# XHSC_HC32F175 register map
Vendor: XHSC Co.Ltd; Series: ARMCM0P; File version: 1.0
CPU: CM0P r0p0, little endian, no MPU, no FPU, 3 interrupt priority bits
Registers are 32-bit, read-write, reset 0x0 unless marked. A register's access mark holds for its fields unless they carry their own. Offsets are from the block's base; [hi:lo] are bit positions; {n}, {i} and the like mark numbered series.

## GPIO
Base 0x40020000
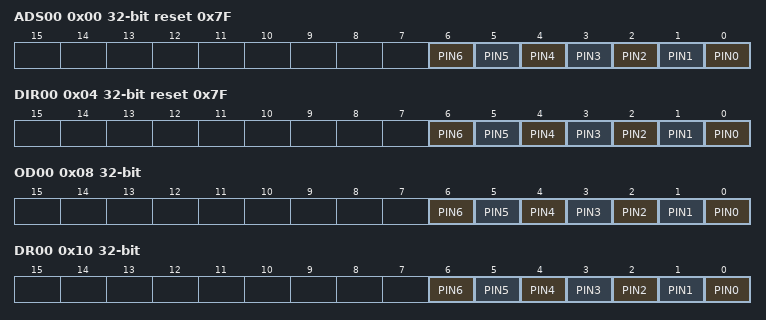
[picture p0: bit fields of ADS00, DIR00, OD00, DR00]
0x00 ADS00 reset 0x7F
  [n] PIN{n} (n=0..6)
0x04 DIR00 reset 0x7F
  [n] PIN{n} (n=0..6)
0x08 OD00
  [n] PIN{n} (n=0..6)
0x10 DR00
  [n] PIN{n} (n=0..6)
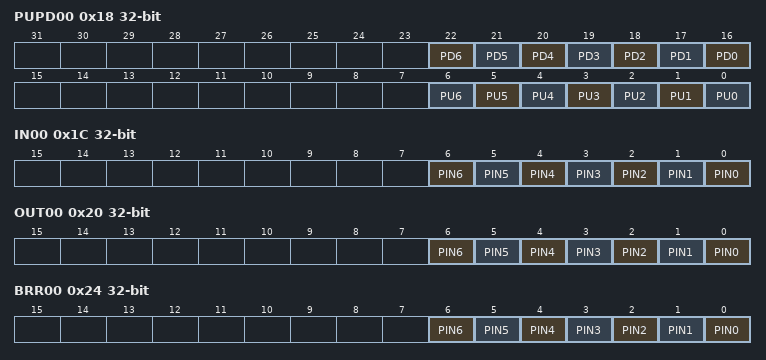
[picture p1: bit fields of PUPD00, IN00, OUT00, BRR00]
0x18 PUPD00
  [n+16] PD{n} (n=0..6), [n] PU{n} (n=0..6)
0x1C IN00 ro
  [n] PIN{n} (n=0..6)
0x20 OUT00
  [n] PIN{n} (n=0..6)
0x24 BRR00 wo
  [n] PIN{n} (n=0..6)
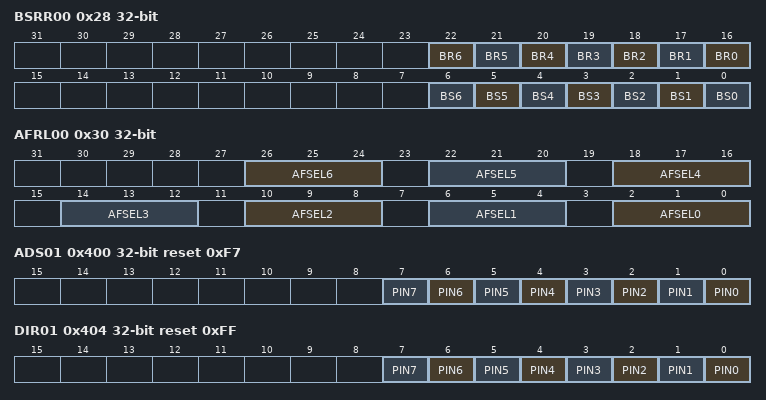
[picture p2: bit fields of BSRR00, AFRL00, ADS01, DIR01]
0x28 BSRR00 wo
  [n+16] BR{n} (n=0..6), [n] BS{n} (n=0..6)
0x30 AFRL00
  [4n+2:4n] AFSEL{n} (n=0..6)
{0x80+0x400*i} LOCK{i:02} wo (i=0..8)
  [31:0] LOCK
0x400 ADS01 reset 0xF7
  [n] PIN{n} (n=0..7)
0x404 DIR01 reset 0xFF
  [n] PIN{n} (n=0..7)
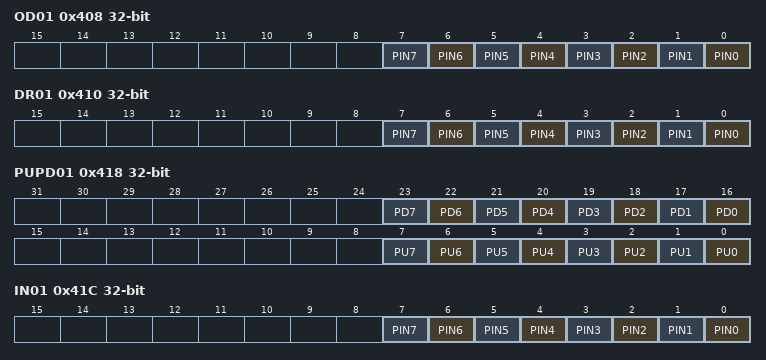
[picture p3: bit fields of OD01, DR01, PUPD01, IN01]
0x408 OD01
  [n] PIN{n} (n=0..7)
0x410 DR01
  [n] PIN{n} (n=0..7)
0x418 PUPD01
  [n+16] PD{n} (n=0..7), [n] PU{n} (n=0..7)
0x41C IN01 ro
  [n] PIN{n} (n=0..7)
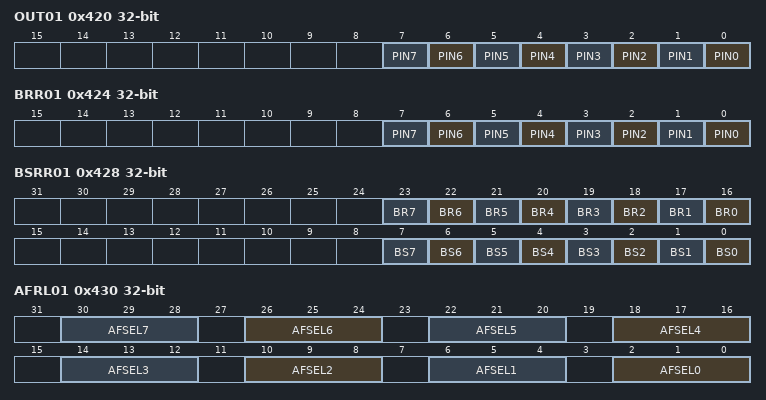
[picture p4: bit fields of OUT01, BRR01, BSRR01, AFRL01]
0x420 OUT01
  [n] PIN{n} (n=0..7)
0x424 BRR01 wo
  [n] PIN{n} (n=0..7)
0x428 BSRR01 wo
  [n+16] BR{n} (n=0..7), [n] BS{n} (n=0..7)
0x430 AFRL01
  [4n+2:4n] AFSEL{n} (n=0..7)
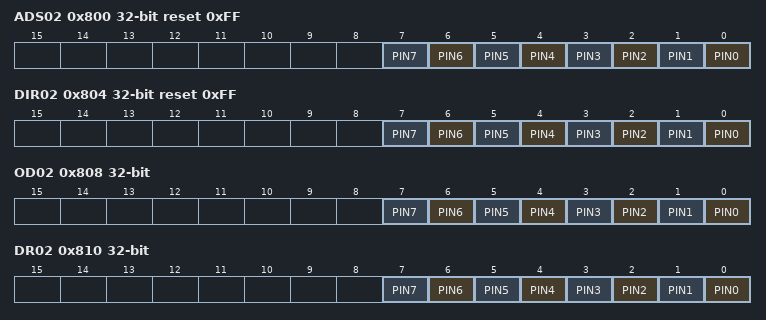
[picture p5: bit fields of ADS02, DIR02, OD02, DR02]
0x800 ADS02 reset 0xFF
  [n] PIN{n} (n=0..7)
0x804 DIR02 reset 0xFF
  [n] PIN{n} (n=0..7)
0x808 OD02
  [n] PIN{n} (n=0..7)
0x810 DR02
  [n] PIN{n} (n=0..7)
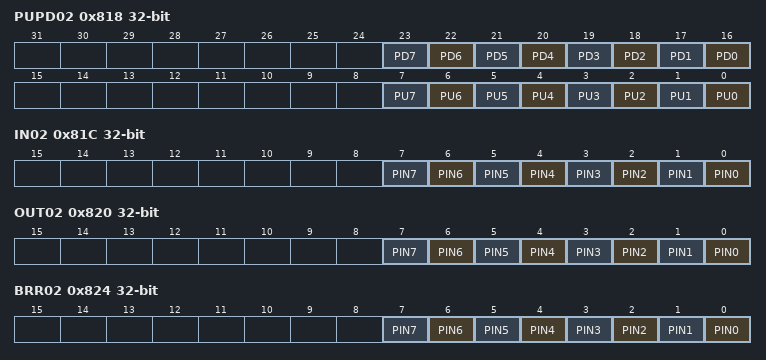
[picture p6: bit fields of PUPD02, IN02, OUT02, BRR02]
0x818 PUPD02
  [n+16] PD{n} (n=0..7), [n] PU{n} (n=0..7)
0x81C IN02 ro
  [n] PIN{n} (n=0..7)
0x820 OUT02
  [n] PIN{n} (n=0..7)
0x824 BRR02 wo
  [n] PIN{n} (n=0..7)
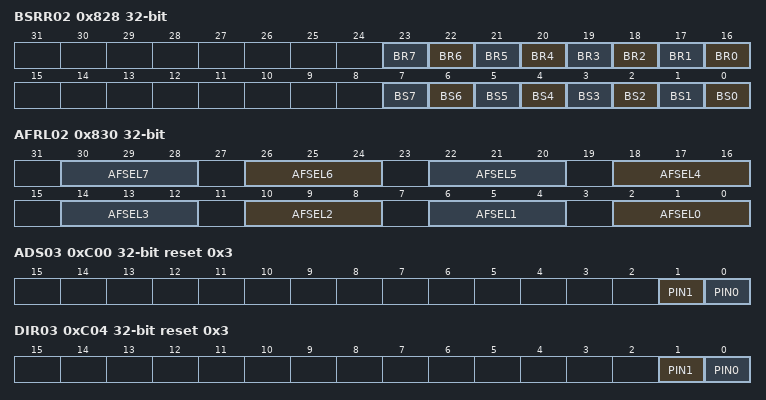
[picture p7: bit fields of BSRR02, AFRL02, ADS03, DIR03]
0x828 BSRR02 wo
  [n+16] BR{n} (n=0..7), [n] BS{n} (n=0..7)
0x830 AFRL02
  [4n+2:4n] AFSEL{n} (n=0..7)
0xC00 ADS03 reset 0x3
  [1] PIN1, [0] PIN0
0xC04 DIR03 reset 0x3
  [1] PIN1, [0] PIN0
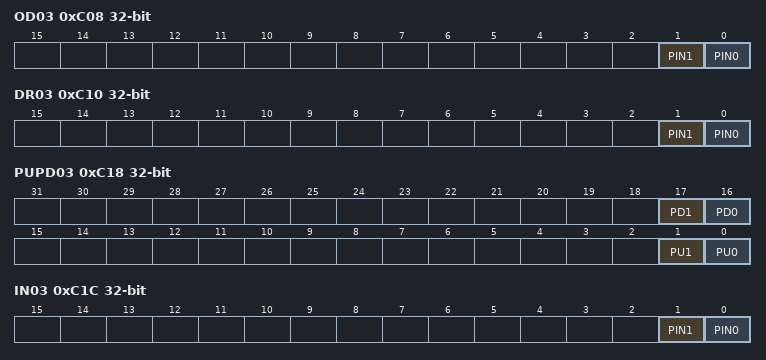
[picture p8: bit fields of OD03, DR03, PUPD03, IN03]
0xC08 OD03
  [1] PIN1, [0] PIN0
0xC10 DR03
  [1] PIN1, [0] PIN0
0xC18 PUPD03
  [17] PD1, [16] PD0, [1] PU1, [0] PU0
0xC1C IN03 ro
  [1] PIN1, [0] PIN0
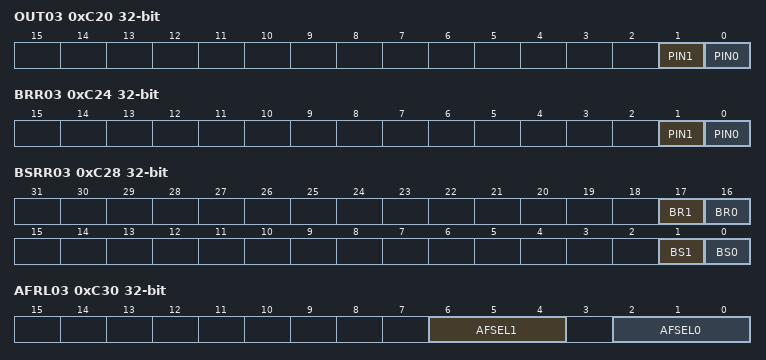
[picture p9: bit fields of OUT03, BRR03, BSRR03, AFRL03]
0xC20 OUT03
  [1] PIN1, [0] PIN0
0xC24 BRR03 wo
  [1] PIN1, [0] PIN0
0xC28 BSRR03 wo
  [17] BR1, [16] BR0, [1] BS1, [0] BS0
0xC30 AFRL03
  [6:4] AFSEL1, [2:0] AFSEL0
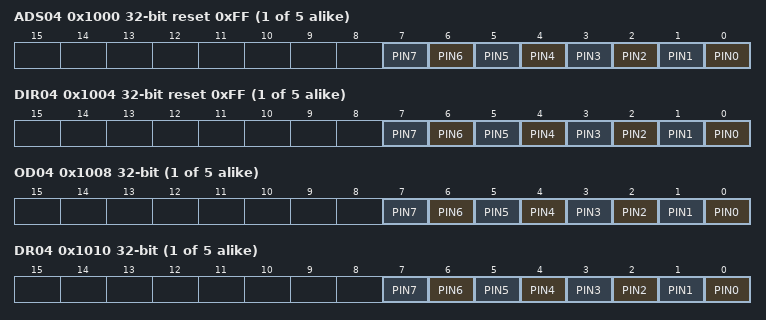
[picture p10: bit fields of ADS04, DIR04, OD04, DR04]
{0x0+0x400*i} ADS{i:02} reset 0xFF (i=4..8)
  [n] PIN{n} (n=0..7)
{0x4+0x400*i} DIR{i:02} reset 0xFF (i=4..8)
  [n] PIN{n} (n=0..7)
{0x8+0x400*i} OD{i:02} (i=4..8)
  [n] PIN{n} (n=0..7)
{0x10+0x400*i} DR{i:02} (i=4..8)
  [n] PIN{n} (n=0..7)
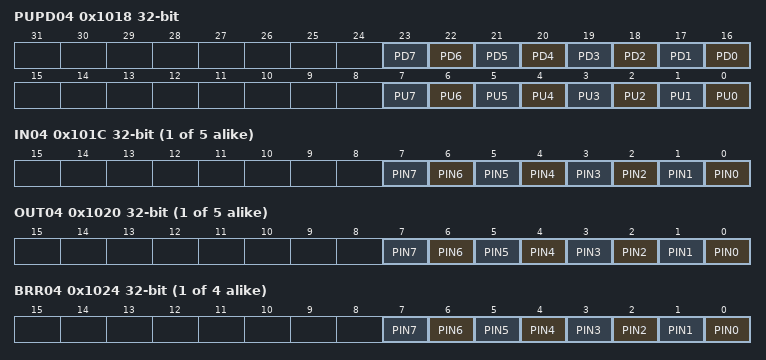
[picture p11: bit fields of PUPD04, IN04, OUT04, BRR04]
0x1018 PUPD04
  [n+16] PD{n} (n=0..7), [n] PU{n} (n=0..7)
{0x1C+0x400*i} IN{i:02} ro (i=4..8)
  [n] PIN{n} (n=0..7)
{0x20+0x400*i} OUT{i:02} (i=4..8)
  [n] PIN{n} (n=0..7)
{0x24+0x400*i} BRR{i:02} wo (i=4..7)
  [n] PIN{n} (n=0..7)
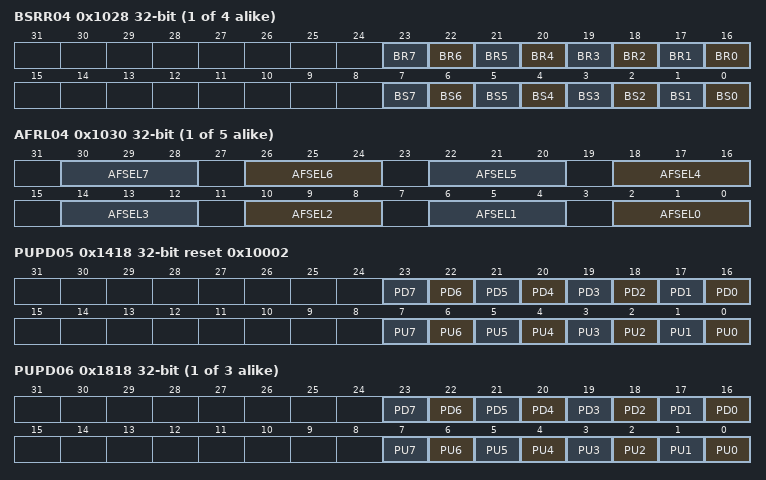
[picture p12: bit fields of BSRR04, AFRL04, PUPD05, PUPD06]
{0x28+0x400*i} BSRR{i:02} wo (i=4..7)
  [n+16] BR{n} (n=0..7), [n] BS{n} (n=0..7)
{0x30+0x400*i} AFRL{i:02} (i=4..8)
  [4n+2:4n] AFSEL{n} (n=0..7)
0x1418 PUPD05 reset 0x10002
  [n+16] PD{n} (n=0..7), [n] PU{n} (n=0..7)
{0x18+0x400*i} PUPD{i:02} (i=6..8)
  [n+16] PD{n} (n=0..7), [n] PU{n} (n=0..7)
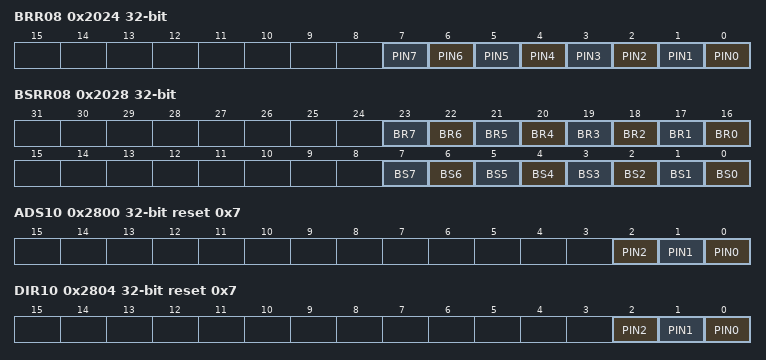
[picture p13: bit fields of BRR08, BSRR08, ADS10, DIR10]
0x2024 BRR08
  [n] PIN{n} wo (n=0..7)
0x2028 BSRR08
  [n+16] BR{n} wo (n=0..7), [n] BS{n} wo (n=0..7)
0x2800 ADS10 reset 0x7
  [2] PIN2, [1] PIN1, [0] PIN0
0x2804 DIR10 reset 0x7
  [2] PIN2, [1] PIN1, [0] PIN0
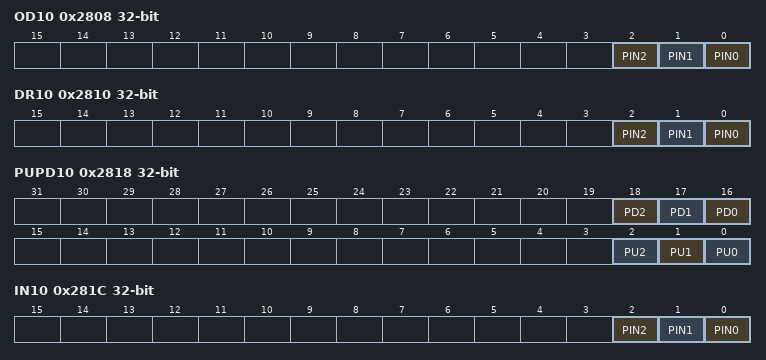
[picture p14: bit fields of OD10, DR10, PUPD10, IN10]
0x2808 OD10
  [2] PIN2, [1] PIN1, [0] PIN0
0x2810 DR10
  [2] PIN2, [1] PIN1, [0] PIN0
0x2818 PUPD10
  [18] PD2, [17] PD1, [16] PD0, [2] PU2, [1] PU1, [0] PU0
0x281C IN10 ro
  [2] PIN2, [1] PIN1, [0] PIN0
0x2820 OUT10
  [2] PIN2, [1] PIN1, [0] PIN0
0x2824 BRR10 wo
  [2] PIN2, [1] PIN1, [0] PIN0
0x2828 BSRR10 wo
  [18] BR2, [17] BR1, [16] BR0, [2] BS2, [1] BS1, [0] BS0
0x2830 AFRL10
  [10:8] AFSEL2, [6:4] AFSEL1, [2:0] AFSEL0
{0x80+0x400*i} LOCK{i} wo (i=10..15)
  [31:0] LOCK
0x2C00 ADS11 reset 0x3
  [1] PIN1, [0] PIN0
0x2C04 DIR11 reset 0x3
  [1] PIN1, [0] PIN0
0x2C08 OD11
  [1] PIN1, [0] PIN0
0x2C10 DR11
  [1] PIN1, [0] PIN0
0x2C18 PUPD11
  [17] PD1, [16] PD0, [1] PU1, [0] PU0
0x2C1C IN11 ro
  [1] PIN1, [0] PIN0
0x2C20 OUT11
  [1] PIN1, [0] PIN0
0x2C24 BRR11 wo
  [1] PIN1, [0] PIN0
0x2C28 BSRR11 wo
  [17] BR1, [16] BR0, [1] BS1, [0] BS0
0x2C30 AFRL11
  [6:4] AFSEL1, [2:0] AFSEL0
0x3000 ADS12 reset 0x1F
  [n] PIN{n} (n=0..4)
0x3004 DIR12 reset 0x1F
  [n] PIN{n} (n=0..4)
0x3008 OD12
  [n] PIN{n} (n=0..4)
0x3010 DR12
  [n] PIN{n} (n=0..4)
0x3018 PUPD12
  [n+16] PD{n} (n=0..4), [n] PU{n} (n=0..4)
0x301C IN12 ro
  [n] PIN{n} (n=0..4)
0x3020 OUT12
  [n] PIN{n} (n=0..4)
0x3024 BRR12 wo
  [n] PIN{n} (n=0..4)
0x3028 BSRR12 wo
  [n+16] BR{n} (n=0..4), [n] BS{n} (n=0..4)
0x3030 AFRL12
  [4n+2:4n] AFSEL{n} (n=0..4)
0x3400 ADS13 reset 0x81
  [7] PIN7, [0] PIN0
0x3404 DIR13 reset 0x81
  [7] PIN7, [0] PIN0
0x3408 OD13
  [7] PIN7, [0] PIN0
0x3410 DR13
  [7] PIN7, [0] PIN0
0x3418 PUPD13
  [23] PD7, [16] PD0, [7] PU7, [0] PU0
0x341C IN13 ro
  [7] PIN7, [0] PIN0
0x3420 OUT13
  [7] PIN7, [0] PIN0
0x3424 BRR13 wo
  [7] PIN7, [0] PIN0
0x3428 BSRR13 wo
  [23] BR7, [16] BR0, [7] BS7, [0] BS0
0x3430 AFRL13
  [30:28] AFSEL7, [2:0] AFSEL0
0x3800 ADS14 reset 0xFF
  [n] PIN{n} (n=0..7)
0x3804 DIR14 reset 0xFF
  [n] PIN{n} (n=0..7)
0x3808 OD14
  [n] PIN{n} (n=0..7)
0x3810 DR14
  [n] PIN{n} (n=0..7)
0x3818 PUPD14
  [n+16] PD{n} (n=0..7), [n] PU{n} (n=0..7)
0x381C IN14 ro
  [n] PIN{n} (n=0..7)
0x3820 OUT14
  [n] PIN{n} (n=0..7)
0x3824 BRR14 wo
  [n] PIN{n} (n=0..7)
0x3828 BSRR14 wo
  [n+16] BR{n} (n=0..7), [n] BS{n} (n=0..7)
0x3830 AFRL14
  [4n+2:4n] AFSEL{n} (n=0..7)
0x3C00 ADS15 reset 0x7F
  [n] PIN{n} (n=0..6)
0x3C04 DIR15 reset 0x7F
  [n] PIN{n} (n=0..6)
0x3C08 OD15
  [n] PIN{n} (n=0..6)
0x3C10 DR15
  [n] PIN{n} (n=0..6)
0x3C18 PUPD15
  [n+16] PD{n} (n=0..6), [n] PU{n} (n=0..6)
0x3C1C IN15 ro
  [n] PIN{n} (n=0..6)
0x3C20 OUT15
  [n] PIN{n} (n=0..6)
0x3C24 BRR15 wo
  [n] PIN{n} (n=0..6)
0x3C28 BSRR15 wo
  [n+16] BR{n} (n=0..6), [n] BS{n} (n=0..6)
0x3C30 AFRL15
  [4n+2:4n] AFSEL{n} (n=0..6)
